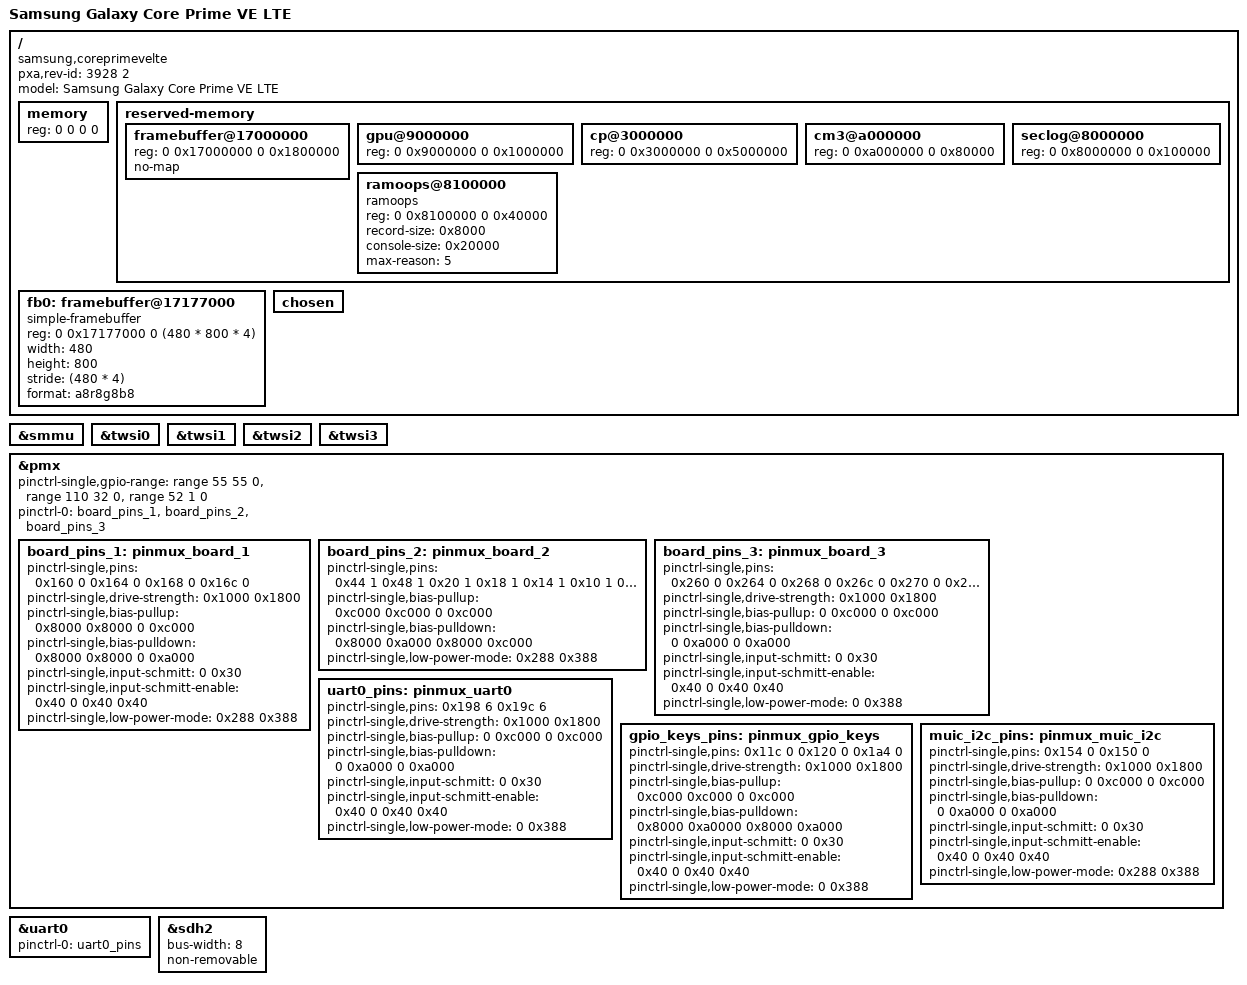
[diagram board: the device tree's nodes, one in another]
#include "armada-pxa1908.dtsi"

/ {
	pxa,rev-id = <3928 2>;
	model = "Samsung Galaxy Core Prime VE LTE";
	compatible = "samsung,coreprimevelte", "marvell,pxa1908";

	/* Bootloader fills this in */
	memory {
		device_type = "memory";
		reg = <0 0 0 0>;
	};

	reserved-memory {
		#address-cells = <2>;
		#size-cells = <2>;
		ranges;

		framebuffer@17000000 {
			reg = <0 0x17000000 0 0x1800000>;
			no-map;
		};

		gpu@9000000 {
			reg = <0 0x9000000 0 0x1000000>;
		};

		/* Communications processor, aka modem */
		cp@3000000 {
			reg = <0 0x3000000 0 0x5000000>;
		};

		cm3@a000000 {
			reg = <0 0xa000000 0 0x80000>;
		};

		seclog@8000000 {
			reg = <0 0x8000000 0 0x100000>;
		};

		ramoops@8100000 {
			compatible = "ramoops";
			reg = <0 0x8100000 0 0x40000>;
			record-size = <0x8000>;
			console-size = <0x20000>;
			max-reason = <5>;
		};
	};

	fb0: framebuffer@17177000 {
		compatible = "simple-framebuffer";
		reg = <0 0x17177000 0 (480 * 800 * 4)>;
		width = <480>;
		height = <800>;
		stride = <(480 * 4)>;
		format = "a8r8g8b8";
	};

	chosen {};
};

&smmu {
	status = "okay";
};

&twsi0 {
	status = "okay";
};

&twsi1 {
	status = "okay";
};

&twsi2 {
	status = "okay";
};

&twsi3 {
	status = "okay";
};

&pmx {
	pinctrl-single,gpio-range = <&range 55 55 0>,
				    <&range 110 32 0>,
				    <&range 52 1 0>;
	
	pinctrl-names = "default";
	pinctrl-0 = <&board_pins_1 &board_pins_2 &board_pins_3>;

	board_pins_1: pinmux_board_1 {
		pinctrl-single,pins = <
			0x160 0
			0x164 0
			0x168 0
			0x16c 0
		>;
		pinctrl-single,drive-strength = <0x1000 0x1800>;
		pinctrl-single,bias-pullup = <0x8000 0x8000 0 0xc000>;
		pinctrl-single,bias-pulldown = <0x8000 0x8000 0 0xa000>;
		pinctrl-single,input-schmitt = <0 0x30>;
		pinctrl-single,input-schmitt-enable = <0x40 0 0x40 0x40>;
		pinctrl-single,low-power-mode = <0x288 0x388>;
	};
	
	board_pins_2: pinmux_board_2 {
		pinctrl-single,pins = <
			0x44 1
			0x48 1
			0x20 1
			0x18 1
			0x14 1
			0x10 1
			0xc 1
			0x8 1
			0x68 1
			0x58 0
			0x54 0
			0x7c 0
			0x6c 0
			0x70 0
			0x4c 1
			0x50 1
			0xac 0
			0x90 0
			0x8c 0
			0x88 0
			0x84 0
			0xc8 0
			0x128 0
			0x190 0
			0x194 0
			0x1a0 0
			0x114 0
			0x118 0
			0x1d8 0
			0x1e4 0
			0xe8 0
			0x100 0
			0x204 0
			0x210 0
			0x218 0
		>;
		pinctrl-single,bias-pullup = <0xc000 0xc000 0 0xc000>;
		pinctrl-single,bias-pulldown = <0x8000 0xa000 0x8000 0xc000>;
		pinctrl-single,low-power-mode = <0x288 0x388>;
	};

	board_pins_3: pinmux_board_3 {
		pinctrl-single,pins = <
			0x260 0
			0x264 0
			0x268 0
			0x26c 0
			0x270 0
			0x274 0
			0x78 0
			0x74 0
			0xb0 1
		>;
		pinctrl-single,drive-strength = <0x1000 0x1800>;
		pinctrl-single,bias-pullup = <0 0xc000 0 0xc000>;
		pinctrl-single,bias-pulldown = <0 0xa000 0 0xa000>;
		pinctrl-single,input-schmitt = <0 0x30>;
		pinctrl-single,input-schmitt-enable = <0x40 0 0x40 0x40>;
		pinctrl-single,low-power-mode = <0 0x388>;
	};

	uart0_pins: pinmux_uart0 {
		pinctrl-single,pins = <
			0x198 6
			0x19c 6
		>;
		pinctrl-single,drive-strength = <0x1000 0x1800>;
		pinctrl-single,bias-pullup = <0 0xc000 0 0xc000>;
		pinctrl-single,bias-pulldown = <0 0xa000 0 0xa000>;
		pinctrl-single,input-schmitt = <0 0x30>;
		pinctrl-single,input-schmitt-enable = <0x40 0 0x40 0x40>;
		pinctrl-single,low-power-mode = <0 0x388>;
	};

	gpio_keys_pins: pinmux_gpio_keys {
		pinctrl-single,pins = <
			0x11c 0
			0x120 0
			0x1a4 0
		>;
		pinctrl-single,drive-strength = <0x1000 0x1800>;
		pinctrl-single,bias-pullup = <0xc000 0xc000 0 0xc000>;
		pinctrl-single,bias-pulldown = <0x8000 0xa0000 0x8000 0xa000>;
		pinctrl-single,input-schmitt = <0 0x30>;
		pinctrl-single,input-schmitt-enable = <0x40 0 0x40 0x40>;
		pinctrl-single,low-power-mode = <0 0x388>;
	};

	muic_i2c_pins: pinmux_muic_i2c {
		pinctrl-single,pins = <
			0x154 0
			0x150 0
		>;
		pinctrl-single,drive-strength = <0x1000 0x1800>;
		pinctrl-single,bias-pullup = <0 0xc000 0 0xc000>;
		pinctrl-single,bias-pulldown = <0 0xa000 0 0xa000>;
		pinctrl-single,input-schmitt = <0 0x30>;
		pinctrl-single,input-schmitt-enable = <0x40 0 0x40 0x40>;
		pinctrl-single,low-power-mode = <0x288 0x388>;
	};
};

&uart0 {
	pinctrl-names = "default";
	pinctrl-0 = <&uart0_pins>;
};

&sdh2 {
	bus-width = <8>;
	non-removable;
};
